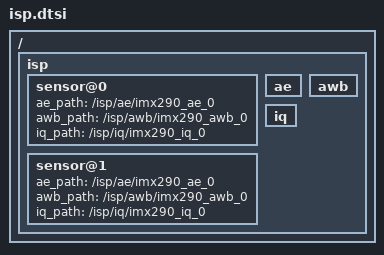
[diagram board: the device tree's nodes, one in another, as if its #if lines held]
/ {
	isp {
		sensor@0 {
			ae_path                 = "/isp/ae/imx290_ae_0";
			awb_path                = "/isp/awb/imx290_awb_0";
			iq_path                 = "/isp/iq/imx290_iq_0";
		};
		sensor@1 {
			ae_path                 = "/isp/ae/imx290_ae_0";
			awb_path                = "/isp/awb/imx290_awb_0";
			iq_path                 = "/isp/iq/imx290_iq_0";
		};
		/* label for ae, awb, iq table */
		ae: ae {
		};
		awb: awb {
		};
		iq: iq {
		};
	};
};

/* Note: put include files in the tail since label should be declared first. */
#if defined(_sen_imx290_)
#include "imx290_ae_0.dtsi"
#include "imx290_awb_0.dtsi"
#include "imx290_iq_0.dtsi"
#endif
#if defined(_sen_os02k10_)
#include "os02k10_ae_0.dtsi"
#include "os02k10_awb_0.dtsi"
#include "os02k10_iq_0.dtsi"
#endif
#if defined(_sen_gc4653_)
#include "gc4653_ae_0.dtsi"
#include "gc4653_awb_0.dtsi"
#include "gc4653_iq_0.dtsi"
#endif

